# rCSL_gpio_001 register map
Vendor: Texas Instruments
Peripheral module from a debugger description file (folder OMAPL138_C6748).
Registers are 32-bit, read-write, reset 0x0 unless marked. A register's access mark holds for its fields unless they carry their own. Offsets are as the file gives them; lines under a group give offsets from that group; [hi:lo] are bit positions; {n}, {i} and the like mark numbered series; 'fields as' and 'values as' point back to an identical list; <NAME> marks a mode.

## GPIO
0x00 REVID ro reset 0x44830105 — Peripheral ID Register
  [31:0] REV — PID
0x08 BINTEN access not given — GPIO Interrupt Per-Bank Enable
  [31:8] _RSVD — (access N)
  [n] EN{n} rw (n=0..8) — Enable Bank {n} Interrupts
    0=DISABLE; 1=ENABLE
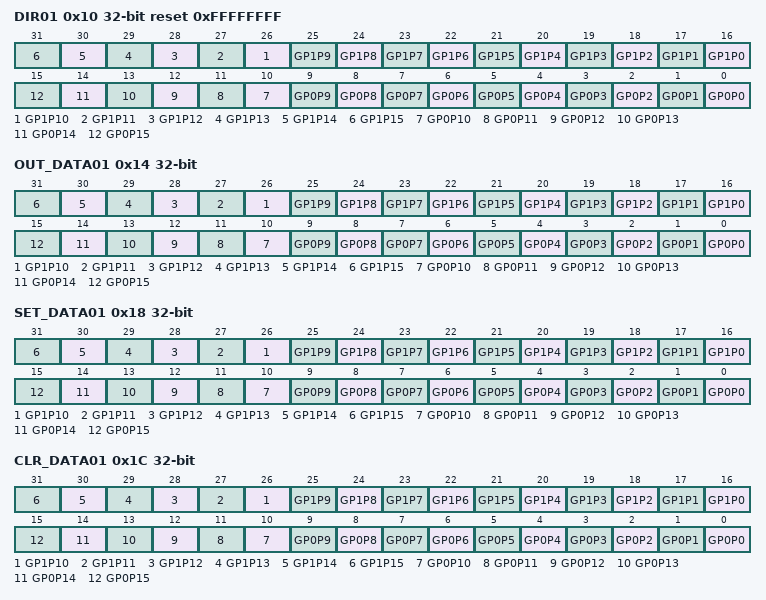
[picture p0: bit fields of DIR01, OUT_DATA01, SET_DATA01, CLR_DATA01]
0x10 DIR01 reset 0xFFFFFFFF — GPIO Direction Bank0 + Bank1
  [all] fields
    0=OUT; 1=IN
  [n+16] GP1P{n} (n=0..15) — Pin direction
  [n] GP0P{n} (n=0..15) — Pin direction
0x14 OUT_DATA01 — GPIO Output Data Bank0 + Bank1
  [all] fields
    0=CLR; 1=SET
  [n+16] GP1P{n} (n=0..15) — Data to output on Pin
  [n] GP0P{n} (n=0..15) — Data to output on Pin
0x18 SET_DATA01 — GPIO Set Data Bank0 + Bank1
  [all] fields
    1=SET
  [n+16] GP1P{n} (n=0..15) — Set output data to high
  [n] GP0P{n} (n=0..15) — Set output data to high
0x1C CLR_DATA01 — GPIO Clear Data Bank0 + Bank1
  [all] fields
    1=CLR
  [n+16] GP1P{n} (n=0..15) — Set output data to low
  [n] GP0P{n} (n=0..15) — Set output data to low
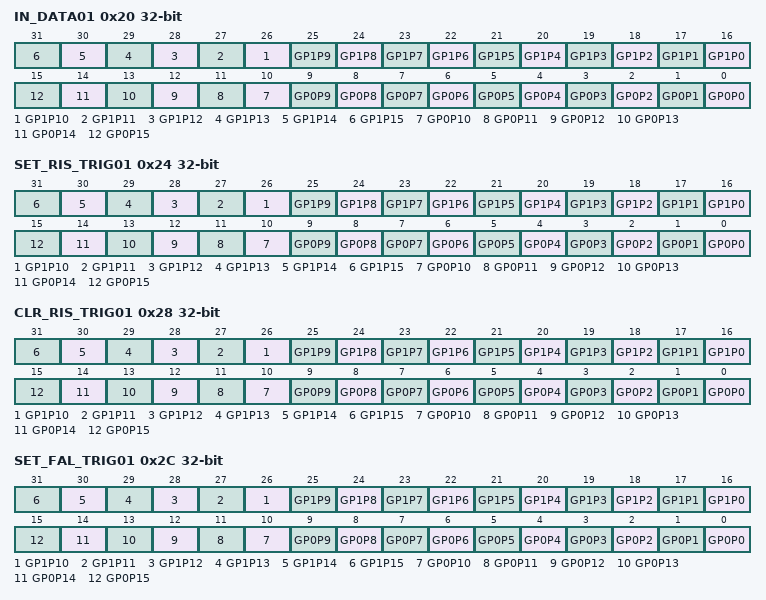
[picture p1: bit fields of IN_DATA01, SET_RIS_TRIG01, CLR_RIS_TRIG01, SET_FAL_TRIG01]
0x20 IN_DATA01 ro — GPIO Input Data Bank0 + Bank1
  [all] fields
    0=CLR; 1=SET
  [n+16] GP1P{n} (n=0..15) — Value on GPIO pin
  [n] GP0P{n} (n=0..15) — Value on GPIO pin
0x24 SET_RIS_TRIG01 — GPIO Set Rising Edge Interrupt Bank0 + Bank1
  [all] fields
    1=ENABLE
  [n+16] GP1P{n} (n=0..15) — Set falling edge trigger
  [n] GP0P{n} (n=0..15) — Set falling edge trigger
0x28 CLR_RIS_TRIG01 — GPIO Clear Rising Edge Interrupt Bank0 + Bank1
  [all] fields
    1=DISABLE
  [n+16] GP1P{n} (n=0..15) — Clear rising edge trigger
  [n] GP0P{n} (n=0..15) — Clear rising edge trigger
0x2C SET_FAL_TRIG01 — GPIO Set Falling Edge Interrupt Bank0 + Bank1
  fields as SET_RIS_TRIG01
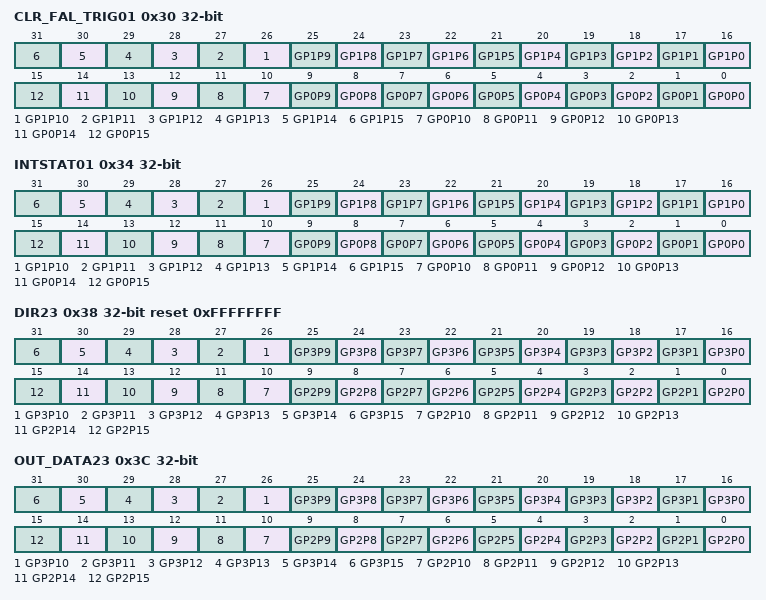
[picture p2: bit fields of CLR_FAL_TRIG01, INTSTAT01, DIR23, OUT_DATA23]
0x30 CLR_FAL_TRIG01 — GPIO Clear Falling Edge Interrupt Bank0 + Bank1
  [all] fields
    1=DISABLE
  [n+16] GP1P{n} (n=0..15) — Clear falling edge trigger
  [n] GP0P{n} (n=0..15) — Clear falling edge trigger
0x34 INTSTAT01 — GPIO Interrupt Status Bank0 + Bank1
  [all] fields
    0=NOPEND; 1=PEND
  [n+16] GP1P{n} (n=0..15) — Pending interrupt status
  [n] GP0P{n} (n=0..15) — Pending interrupt status
0x38 DIR23 reset 0xFFFFFFFF — GPIO Direction Bank2 + Bank3
  [all] fields
    0=OUT; 1=IN
  [n+16] GP3P{n} (n=0..15) — Pin direction
  [n] GP2P{n} (n=0..15) — Pin direction
0x3C OUT_DATA23 — GPIO Output Data Bank2 + Bank3
  [all] fields
    0=CLR; 1=SET
  [n+16] GP3P{n} (n=0..15) — Data to output on Pin
  [n] GP2P{n} (n=0..15) — Data to output on Pin
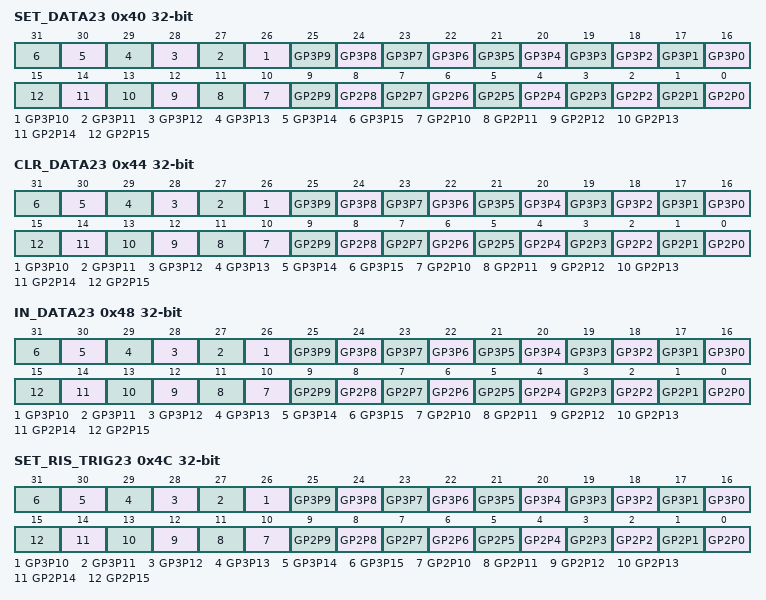
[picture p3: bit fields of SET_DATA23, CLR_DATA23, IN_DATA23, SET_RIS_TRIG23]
0x40 SET_DATA23 — GPIO Set Data Bank2 + Bank3
  [all] fields
    1=SET
  [n+16] GP3P{n} (n=0..15) — Set output data to high
  [n] GP2P{n} (n=0..15) — Set output data to high
0x44 CLR_DATA23 — GPIO Clear Data Bank2 + Bank3
  [all] fields
    1=CLR
  [n+16] GP3P{n} (n=0..15) — Set output data to low
  [n] GP2P{n} (n=0..15) — Set output data to low
0x48 IN_DATA23 ro — GPIO Input Data Bank2 + Bank3
  [all] fields
    0=CLR; 1=SET
  [n+16] GP3P{n} (n=0..15) — Value on GPIO pin
  [n] GP2P{n} (n=0..15) — Value on GPIO pin
0x4C SET_RIS_TRIG23 — GPIO Set Rising Edge Interrupt Bank2 + Bank3
  [all] fields
    1=ENABLE
  [n+16] GP3P{n} (n=0..15) — Set rising edge trigger
  [n] GP2P{n} (n=0..15) — Set rising edge trigger
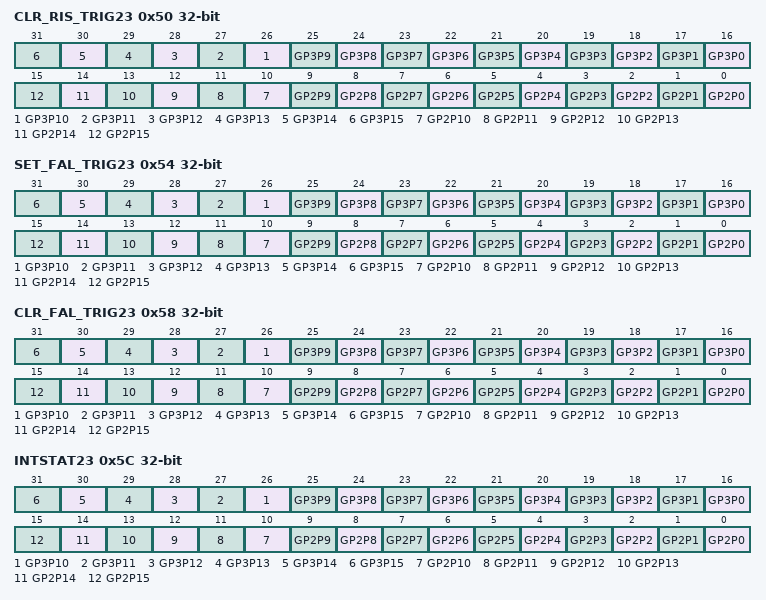
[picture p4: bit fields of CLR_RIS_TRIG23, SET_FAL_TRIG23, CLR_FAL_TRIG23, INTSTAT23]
0x50 CLR_RIS_TRIG23 — GPIO Clear Rising Edge Interrupt Bank2 + Bank3
  [all] fields
    1=DISABLE
  [n+16] GP3P{n} (n=0..15) — Clear rising edge trigger
  [n] GP2P{n} (n=0..15) — Clear rising edge trigger
0x54 SET_FAL_TRIG23 — GPIO Set Falling Edge Interrupt Bank2 + Bank3
  [all] fields
    1=ENABLE
  [n+16] GP3P{n} (n=0..15) — Set falling edge trigger
  [n] GP2P{n} (n=0..15) — Set falling edge trigger
0x58 CLR_FAL_TRIG23 — GPIO Clear Falling Edge Interrupt Bank2 + Bank3
  [all] fields
    1=DISABLE
  [n+16] GP3P{n} (n=0..15) — Clear falling edge trigger
  [n] GP2P{n} (n=0..15) — Clear falling edge trigger
0x5C INTSTAT23 — GPIO Interrupt Status Bank2 + Bank3
  [all] fields
    0=NOPEND; 1=PEND
  [n+16] GP3P{n} (n=0..15) — Pending interrupt status
  [n] GP2P{n} (n=0..15) — Pending interrupt status
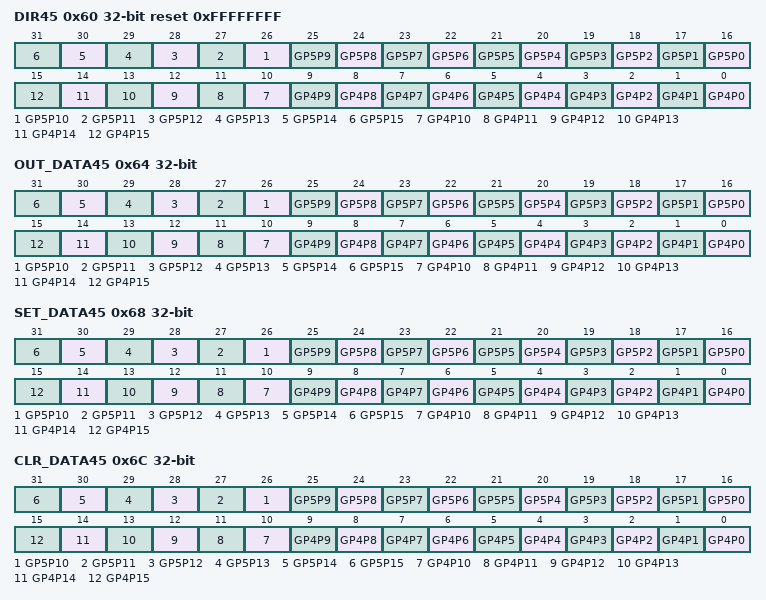
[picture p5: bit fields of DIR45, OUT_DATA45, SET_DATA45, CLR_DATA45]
0x60 DIR45 reset 0xFFFFFFFF — GPIO Direction Bank4 + Bank5
  [all] fields
    0=OUT; 1=IN
  [n+16] GP5P{n} (n=0..15) — Pin direction
  [n] GP4P{n} (n=0..15) — Pin direction
0x64 OUT_DATA45 — GPIO Output Data Bank4 + Bank5
  [all] fields
    0=CLR; 1=SET
  [n+16] GP5P{n} (n=0..15) — Data to output on Pin
  [n] GP4P{n} (n=0..15) — Data to output on Pin
0x68 SET_DATA45 — GPIO Set Data Bank4 + Bank5
  [all] fields
    1=SET
  [n+16] GP5P{n} (n=0..15) — Set output data to high
  [n] GP4P{n} (n=0..15) — Set output data to high
0x6C CLR_DATA45 — GPIO Clear Data Bank4 + Bank5
  [all] fields
    1=CLR
  [n+16] GP5P{n} (n=0..15) — Set output data to low
  [n] GP4P{n} (n=0..15) — Set output data to low
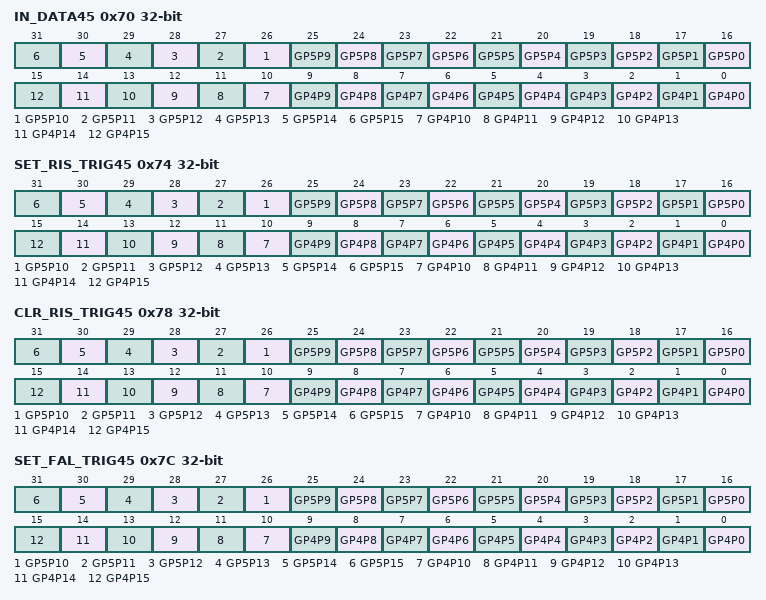
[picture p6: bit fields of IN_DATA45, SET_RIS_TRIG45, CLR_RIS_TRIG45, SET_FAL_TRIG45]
0x70 IN_DATA45 ro — GPIO Input Data Bank4 + Bank5
  [all] fields
    0=CLR; 1=SET
  [n+16] GP5P{n} (n=0..15) — Value on GPIO pin
  [n] GP4P{n} (n=0..15) — Value on GPIO pin
0x74 SET_RIS_TRIG45 — GPIO Set Rising Edge Interrupt Bank4 + Bank5
  [all] fields
    1=ENABLE
  [n+16] GP5P{n} (n=0..15) — Set rising edge trigger
  [n] GP4P{n} (n=0..15) — Set rising edge trigger
0x78 CLR_RIS_TRIG45 — GPIO Clear Rising Edge Interrupt Bank4 + Bank5
  [all] fields
    1=DISABLE
  [n+16] GP5P{n} (n=0..15) — Clear rising edge trigger
  [n] GP4P{n} (n=0..15) — Clear rising edge trigger
0x7C SET_FAL_TRIG45 — GPIO Set Falling Edge Interrupt Bank4 + Bank5
  [all] fields
    1=ENABLE
  [n+16] GP5P{n} (n=0..15) — Set falling edge trigger
  [n] GP4P{n} (n=0..15) — Set falling edge trigger
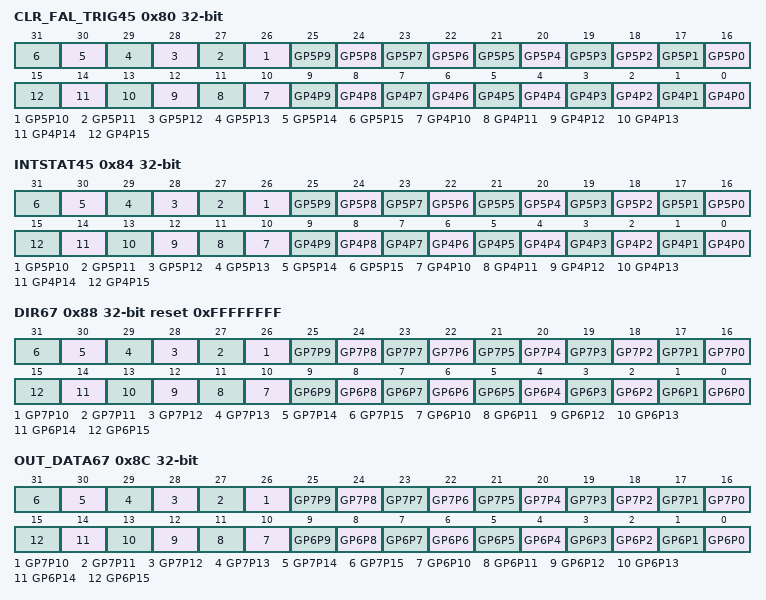
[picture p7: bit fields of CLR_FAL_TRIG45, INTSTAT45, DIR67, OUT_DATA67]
0x80 CLR_FAL_TRIG45 — GPIO Clear Falling Edge Interrupt Bank4 + Bank5
  [all] fields
    1=DISABLE
  [n+16] GP5P{n} (n=0..15) — Clear falling edge trigger
  [n] GP4P{n} (n=0..15) — Clear falling edge trigger
0x84 INTSTAT45 — GPIO Interrupt Status Bank4 + Bank5
  [all] fields
    0=NOPEND; 1=PEND
  [n+16] GP5P{n} (n=0..15) — Pending interrupt status
  [n] GP4P{n} (n=0..15) — Pending interrupt status
0x88 DIR67 reset 0xFFFFFFFF — GPIO Direction Bank6 + Bank7
  [all] fields
    0=OUT; 1=IN
  [n+16] GP7P{n} (n=0..15) — Pin direction
  [n] GP6P{n} (n=0..15) — Pin direction
0x8C OUT_DATA67 — GPIO Output Data Bank6 + Bank7
  [all] fields
    0=CLR; 1=SET
  [n+16] GP7P{n} (n=0..15) — Data to output on Pin
  [n] GP6P{n} (n=0..15) — Data to output on Pin
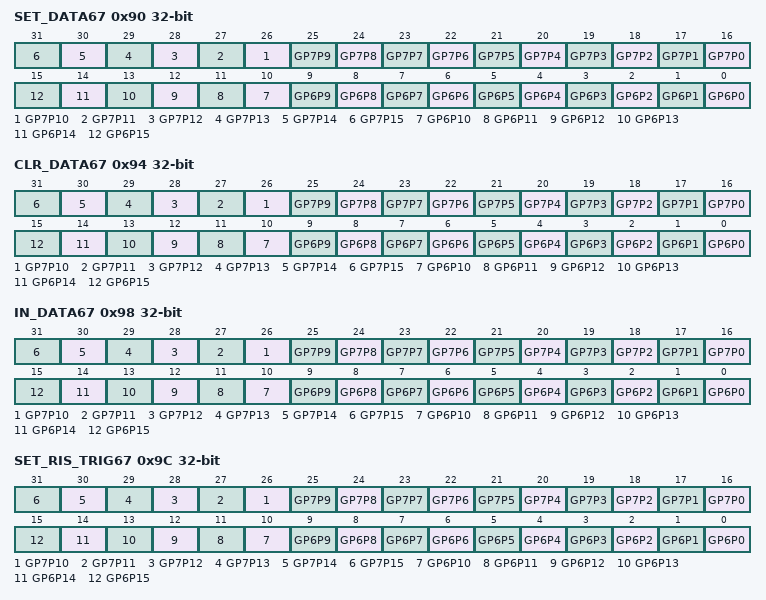
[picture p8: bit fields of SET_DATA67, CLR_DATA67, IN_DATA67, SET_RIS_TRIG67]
0x90 SET_DATA67 — GPIO Set Data Bank6 + Bank7
  [all] fields
    1=SET
  [n+16] GP7P{n} (n=0..15) — Set output data to high
  [n] GP6P{n} (n=0..15) — Set output data to high
0x94 CLR_DATA67 — GPIO Clear Data Bank6 + Bank7
  [all] fields
    1=CLR
  [n+16] GP7P{n} (n=0..15) — Set output data to low
  [n] GP6P{n} (n=0..15) — Set output data to low
0x98 IN_DATA67 ro — GPIO Input Data Bank6 + Bank7
  [all] fields
    0=CLR; 1=SET
  [n+16] GP7P{n} (n=0..15) — Value on GPIO pin
  [n] GP6P{n} (n=0..15) — Value on GPIO pin
0x9C SET_RIS_TRIG67 — GPIO Set Rising Edge Interrupt Bank6 + Bank7
  [all] fields
    1=ENABLE
  [n+16] GP7P{n} (n=0..15) — Set rising edge trigger
  [n] GP6P{n} (n=0..15) — Set rising edge trigger
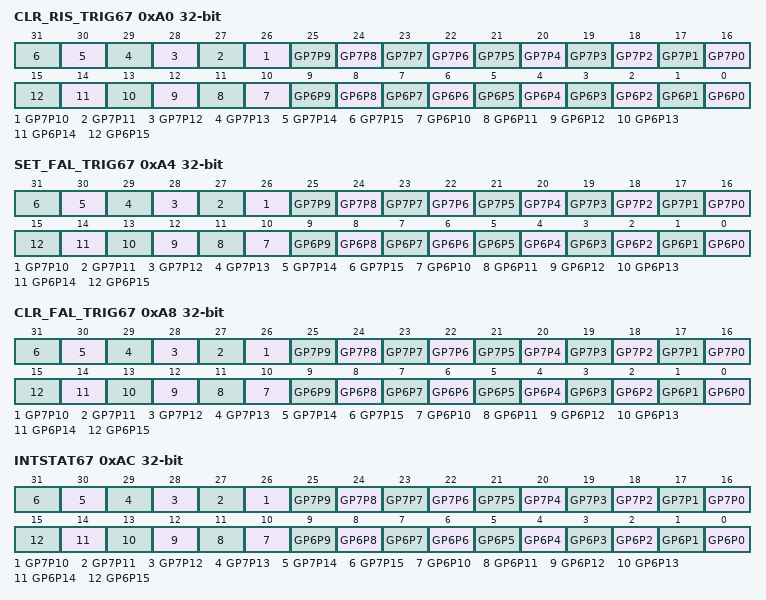
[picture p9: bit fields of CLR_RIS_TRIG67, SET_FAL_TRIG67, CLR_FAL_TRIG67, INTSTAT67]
0xA0 CLR_RIS_TRIG67 — GPIO Clear Rising Edge Interrupt Bank6 + Bank7
  [all] fields
    1=DISABLE
  [n+16] GP7P{n} (n=0..15) — Clear rising edge trigger
  [n] GP6P{n} (n=0..15) — Clear rising edge trigger
0xA4 SET_FAL_TRIG67 — GPIO Set Falling Edge Interrupt Bank6 + Bank7
  [all] fields
    1=ENABLE
  [n+16] GP7P{n} (n=0..15) — Set falling edge trigger
  [n] GP6P{n} (n=0..15) — Set falling edge trigger
0xA8 CLR_FAL_TRIG67 — GPIO Clear Falling Edge Interrupt Bank6 + Bank7
  [all] fields
    1=DISABLE
  [n+16] GP7P{n} (n=0..15) — Clear falling edge trigger
  [n] GP6P{n} (n=0..15) — Clear falling edge trigger
0xAC INTSTAT67 — GPIO Interrupt Status Bank6 + Bank7
  [all] fields
    0=NOPEND; 1=PEND
  [n+16] GP7P{n} (n=0..15) — Pending interrupt status
  [n] GP6P{n} (n=0..15) — Pending interrupt status
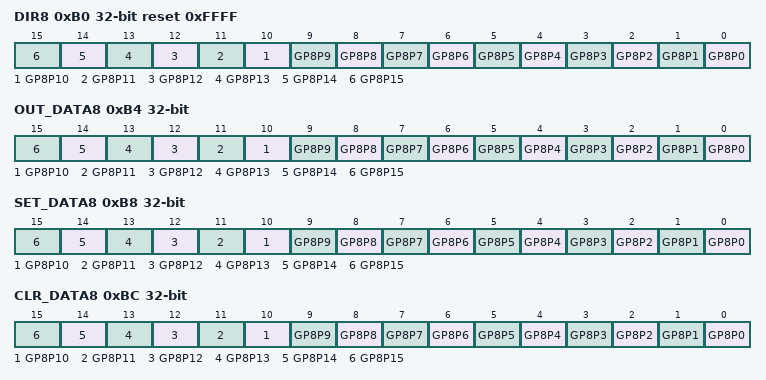
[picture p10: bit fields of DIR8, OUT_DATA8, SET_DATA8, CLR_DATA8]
0xB0 DIR8 access not given reset 0xFFFF — GPIO Direction Bank8
  [all] fields
    0=OUT; 1=IN
  [n] GP8P{n} rw (n=0..15) — Pin direction
0xB4 OUT_DATA8 access not given — GPIO Output Data Bank8
  [all] fields
    0=CLR; 1=SET
  [n] GP8P{n} rw (n=0..15) — Data to output on Pin
0xB8 SET_DATA8 access not given — GPIO Set Data Bank8
  [all] fields
    1=SET
  [n] GP8P{n} rw (n=0..15) — Set output data to high
0xBC CLR_DATA8 access not given — GPIO Clear Data Bank8
  [all] fields
    1=CLR
  [n] GP8P{n} rw (n=0..15) — Set output data to low
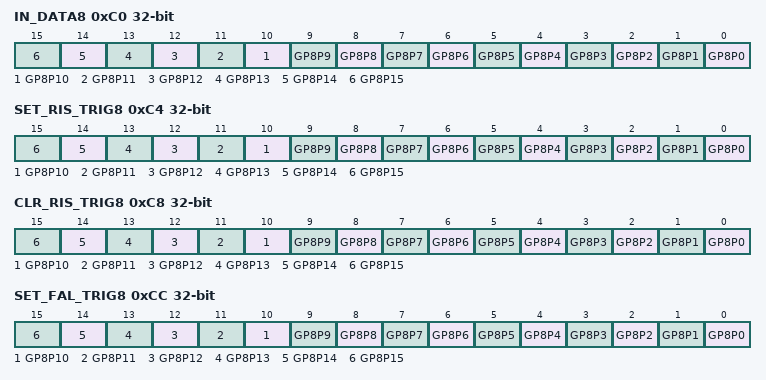
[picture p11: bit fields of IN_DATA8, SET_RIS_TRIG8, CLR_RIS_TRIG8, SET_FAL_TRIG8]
0xC0 IN_DATA8 access not given — GPIO Input Data Bank8
  [all] fields
    0=CLR; 1=SET
  [n] GP8P{n} ro (n=0..15) — Value on GPIO pin
0xC4 SET_RIS_TRIG8 access not given — GPIO Set Rising Edge Interrupt Bank8
  [all] fields
    1=ENABLE
  [n] GP8P{n} rw (n=0..15) — Set rising edge trigger
0xC8 CLR_RIS_TRIG8 access not given — GPIO Clear Rising Edge Interrupt Bank8
  [all] fields
    1=DISABLE
  [n] GP8P{n} rw (n=0..15) — Clear rising edge trigger
0xCC SET_FAL_TRIG8 access not given — GPIO Set Falling Edge Interrupt Bank8
  [all] fields
    1=ENABLE
  [n] GP8P{n} rw (n=0..15) — Set falling edge trigger
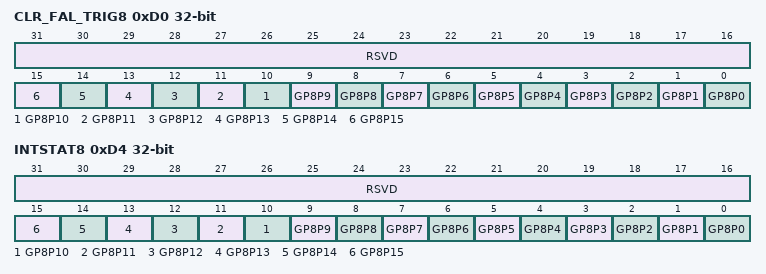
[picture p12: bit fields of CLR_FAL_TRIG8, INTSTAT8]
0xD0 CLR_FAL_TRIG8 access not given — GPIO Clear Falling Edge Interrupt Bank8
  [31:16] RSVD — (access N)
  [n] GP8P{n} rw (n=0..15) — Clear falling edge trigger
    1=DISABLE
0xD4 INTSTAT8 access not given — GPIO Interrupt Status Bank8
  [31:16] RSVD — (access N)
  [n] GP8P{n} rw (n=0..15) — Pending interrupt status
    0=NOPEND; 1=PEND
